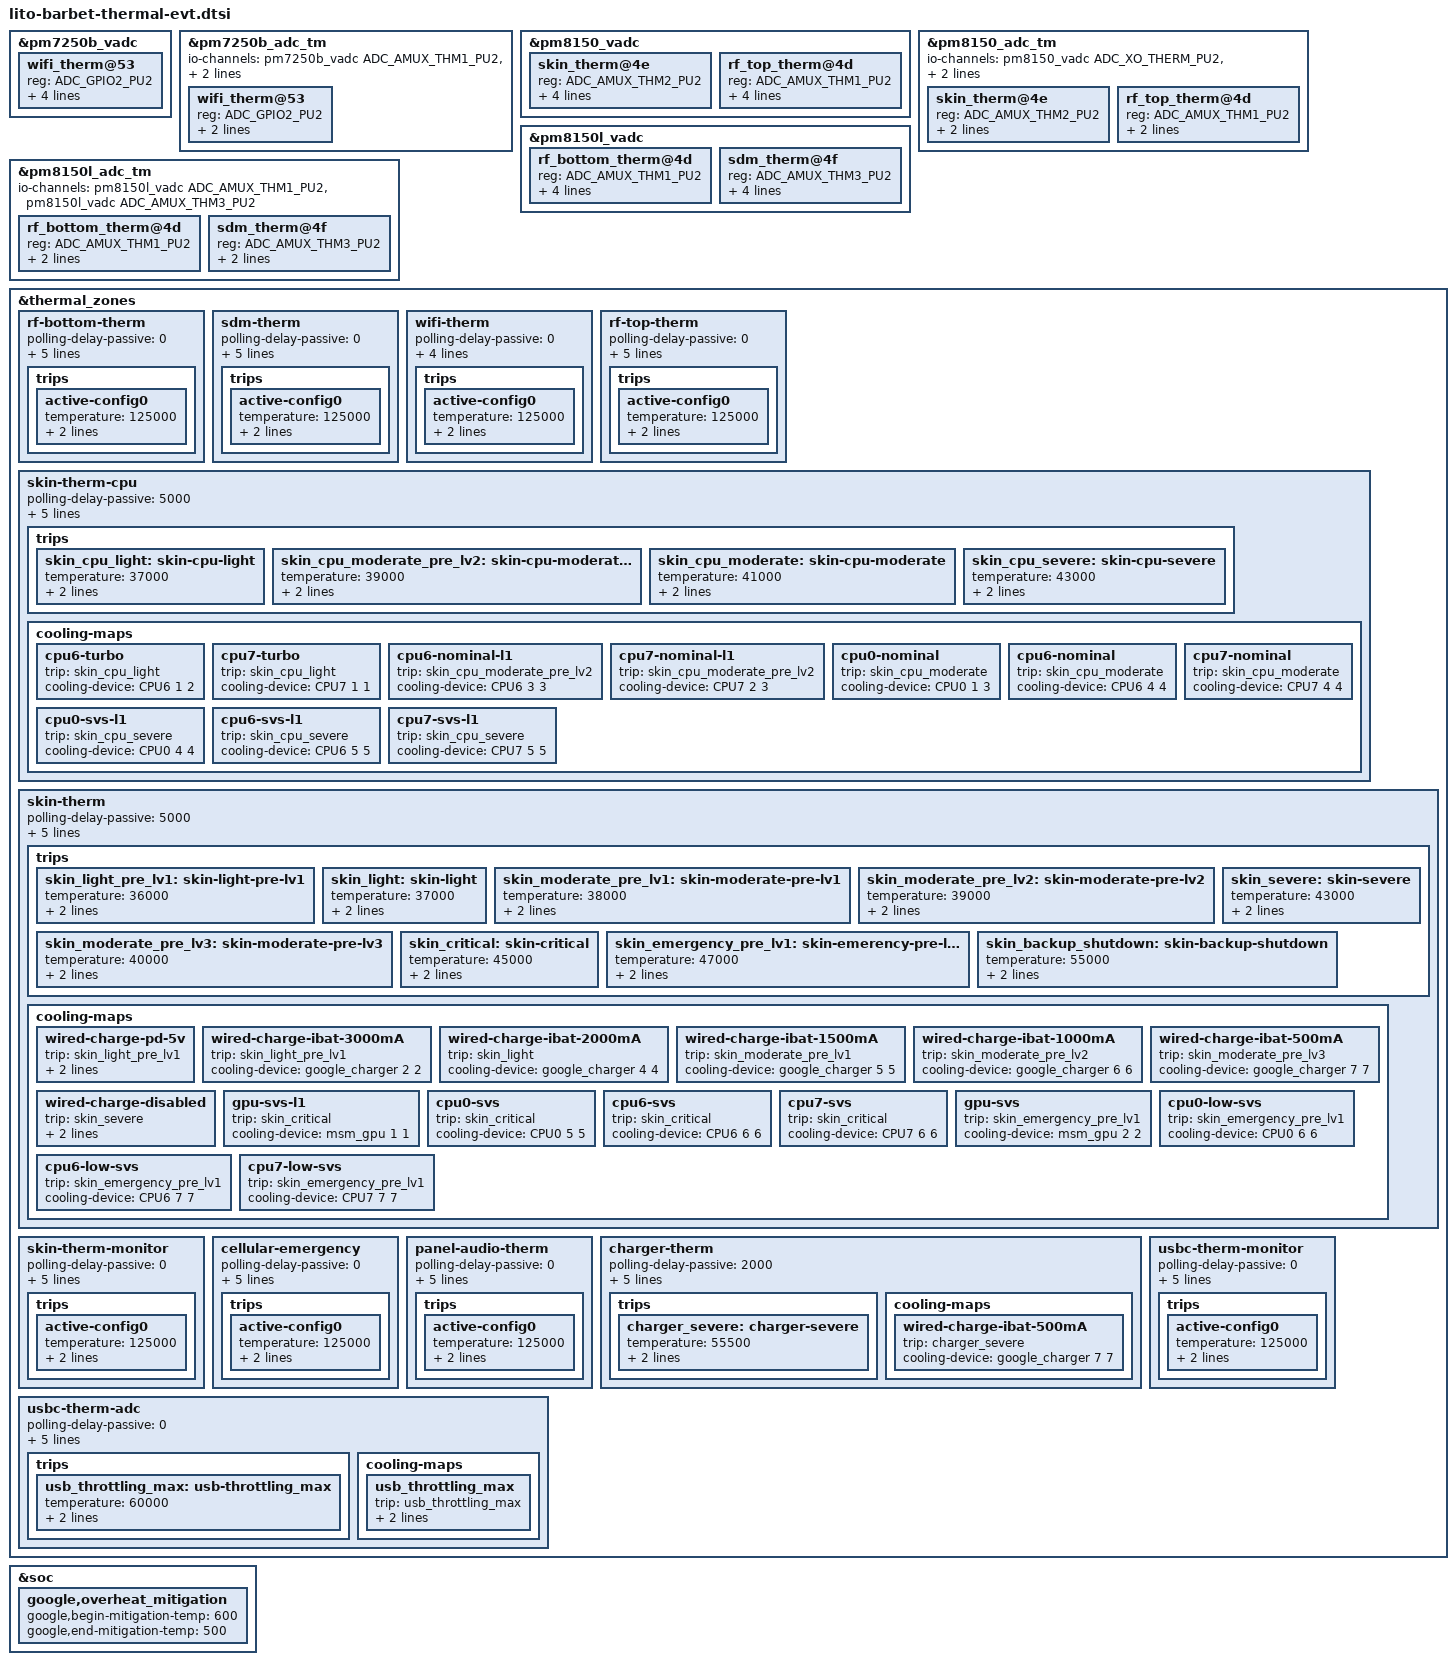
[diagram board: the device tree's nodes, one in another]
// SPDX-License-Identifier: GPL-2.0
/* Copyright (c) 2019, The Linux Foundation. All rights reserved.
 *
 * This program is free software; you can redistribute it and/or modify
 * it under the terms of the GNU General Public License version 2 and
 * only version 2 as published by the Free Software Foundation.
 *
 * This program is distributed in the hope that it will be useful,
 * but WITHOUT ANY WARRANTY; without even the implied warranty of
 * MERCHANTABILITY or FITNESS FOR A PARTICULAR PURPOSE.  See the
 * GNU General Public License for more details.
 */

&pm7250b_vadc {
	wifi_therm@53 {
		reg = <ADC_GPIO2_PU2>;
		label = "wifi_therm";
		qcom,ratiometric;
		qcom,hw-settle-time = <200>;
		qcom,pre-scaling = <1 1>;
	};
};

&pm7250b_adc_tm {
	io-channels = <&pm7250b_vadc ADC_AMUX_THM1_PU2>,
			<&pm7250b_vadc ADC_AMUX_THM3_PU2>,
			<&pm7250b_vadc ADC_GPIO2_PU2>;

	wifi_therm@53 {
		reg = <ADC_GPIO2_PU2>;
		qcom,ratiometric;
		qcom,hw-settle-time = <200>;
	};
};

&pm8150_vadc {
	skin_therm@4e {
		reg = <ADC_AMUX_THM2_PU2>;
		label = "skin_therm";
		qcom,ratiometric;
		qcom,hw-settle-time = <200>;
		qcom,pre-scaling = <1 1>;
	};

	rf_top_therm@4d {
		reg = <ADC_AMUX_THM1_PU2>;
		label = "rf_top_therm";
		qcom,ratiometric;
		qcom,hw-settle-time = <200>;
		qcom,pre-scaling = <1 1>;
	};
};

&pm8150_adc_tm {
	io-channels = <&pm8150_vadc ADC_XO_THERM_PU2>,
			<&pm8150_vadc ADC_AMUX_THM1_PU2>,
			<&pm8150_vadc ADC_AMUX_THM2_PU2>;

	skin_therm@4e {
		reg = <ADC_AMUX_THM2_PU2>;
		qcom,ratiometric;
		qcom,hw-settle-time = <200>;
	};

	rf_top_therm@4d {
		reg = <ADC_AMUX_THM1_PU2>;
		qcom,ratiometric;
		qcom,hw-settle-time = <200>;
	};
};

&pm8150l_vadc {

	rf_bottom_therm@4d {
		reg = <ADC_AMUX_THM1_PU2>;
		label = "rf_bottom_therm";
		qcom,ratiometric;
		qcom,hw-settle-time = <200>;
		qcom,pre-scaling = <1 1>;
	};

	sdm_therm@4f {
		reg = <ADC_AMUX_THM3_PU2>;
		label = "sdm_therm";
		qcom,ratiometric;
		qcom,hw-settle-time = <200>;
		qcom,pre-scaling = <1 1>;
	};
};

&pm8150l_adc_tm {
	io-channels = <&pm8150l_vadc ADC_AMUX_THM1_PU2>,
			<&pm8150l_vadc ADC_AMUX_THM3_PU2>;

	/* Channel nodes */
	rf_bottom_therm@4d {
		reg = <ADC_AMUX_THM1_PU2>;
		qcom,ratiometric;
		qcom,hw-settle-time = <200>;
	};

	sdm_therm@4f {
		reg = <ADC_AMUX_THM3_PU2>;
		qcom,ratiometric;
		qcom,hw-settle-time = <200>;
	};
};

&thermal_zones {
	rf-bottom-therm {
		polling-delay-passive = <0>;
		polling-delay = <0>;
		thermal-governor = "user_space";
		thermal-sensors = <&pm8150l_adc_tm ADC_AMUX_THM1_PU2>;
		wake-capable-sensor;
		trips {
			active-config0 {
				temperature = <125000>;
				hysteresis = <1000>;
				type = "passive";
			};
		};
	};

	sdm-therm {
		polling-delay-passive = <0>;
		polling-delay = <0>;
		thermal-governor = "user_space";
		thermal-sensors = <&pm8150l_adc_tm ADC_AMUX_THM3_PU2>;
		wake-capable-sensor;
		trips {
			active-config0 {
				temperature = <125000>;
				hysteresis = <1000>;
				type = "passive";
			};
		};
	};

	wifi-therm {
		polling-delay-passive = <0>;
		polling-delay = <0>;
		thermal-governor = "user_space";
		thermal-sensors = <&pm7250b_adc_tm ADC_GPIO2_PU2>;
		wake-capable-sensor;
		trips {
			active-config0 {
				temperature = <125000>;
				hysteresis = <1000>;
				type = "passive";
			};
		};
	};

	rf-top-therm {
		polling-delay-passive = <0>;
		polling-delay = <0>;
		thermal-governor = "user_space";
		thermal-sensors = <&pm8150_adc_tm ADC_AMUX_THM1_PU2>;
		wake-capable-sensor;
		trips {
			active-config0 {
				temperature = <125000>;
				hysteresis = <1000>;
				type = "passive";
			};
		};
	};

	skin-therm-cpu {
		polling-delay-passive = <5000>;
		polling-delay = <300000>;
		thermal-governor = "step_wise";
		thermal-sensors = <&pm8150_adc_tm ADC_AMUX_THM2_PU2>;
		wake-capable-sensor;
		trips {
			skin_cpu_light: skin-cpu-light {
				temperature = <37000>;
				hysteresis = <1000>;
				type = "passive";
			};
			skin_cpu_moderate_pre_lv2: skin-cpu-moderate-pre-lv2 {
				temperature = <39000>;
				hysteresis = <1000>;
				type = "passive";
			};
			skin_cpu_moderate: skin-cpu-moderate {
				temperature = <41000>;
				hysteresis = <1000>;
				type = "passive";
			};
			skin_cpu_severe: skin-cpu-severe {
				temperature = <43000>;
				hysteresis = <1000>;
				type = "passive";
			};
		};
		cooling-maps {
			/* light throttling */
			cpu6-turbo {
				trip = <&skin_cpu_light>;
				cooling-device =
					<&CPU6 1 2>;
			};
			cpu7-turbo {
				trip = <&skin_cpu_light>;
				cooling-device =
					<&CPU7 1 1>;
			};
			/* moderate pre level 2 throttling */
			cpu6-nominal-l1 {
				trip = <&skin_cpu_moderate_pre_lv2>;
				cooling-device =
					<&CPU6 3 3>;
			};
			cpu7-nominal-l1 {
				trip = <&skin_cpu_moderate_pre_lv2>;
				cooling-device =
					<&CPU7 2 3>;
			};
			/* moderate throttling */
			cpu0-nominal {
				trip = <&skin_cpu_moderate>;
				cooling-device =
					<&CPU0 1 3>;
			};
			cpu6-nominal {
				trip = <&skin_cpu_moderate>;
				cooling-device =
					<&CPU6 4 4>;
			};
			cpu7-nominal {
				trip = <&skin_cpu_moderate>;
				cooling-device =
					<&CPU7 4 4>;
			};
			/* severe throttling */
			cpu0-svs-l1 {
				trip = <&skin_cpu_severe>;
				cooling-device =
					<&CPU0 4 4>;
			};
			cpu6-svs-l1 {
				trip = <&skin_cpu_severe>;
				cooling-device =
					<&CPU6 5 5>;
			};
			cpu7-svs-l1 {
				trip = <&skin_cpu_severe>;
				cooling-device =
					<&CPU7 5 5>;
			};
		};
	};

	skin-therm {
		polling-delay-passive = <5000>;
		polling-delay = <300000>;
		thermal-governor = "step_wise";
		thermal-sensors = <&pm8150_adc_tm ADC_AMUX_THM2_PU2>;
		wake-capable-sensor;
		trips {
			skin_light_pre_lv1: skin-light-pre-lv1 {
				temperature = <36000>;
				hysteresis = <1000>;
				type = "passive";
			};
			skin_light: skin-light {
				temperature = <37000>;
				hysteresis = <1000>;
				type = "passive";
			};
			skin_moderate_pre_lv1: skin-moderate-pre-lv1 {
				temperature = <38000>;
				hysteresis = <1000>;
				type = "passive";
			};
			skin_moderate_pre_lv2: skin-moderate-pre-lv2 {
				temperature = <39000>;
				hysteresis = <1000>;
				type = "passive";
			};
			skin_moderate_pre_lv3: skin-moderate-pre-lv3 {
				temperature = <40000>;
				hysteresis = <1000>;
				type = "passive";
			};
			skin_severe: skin-severe {
				temperature = <43000>;
				hysteresis = <1000>;
				type = "passive";
			};
			skin_critical: skin-critical {
				temperature = <45000>;
				hysteresis = <1000>;
				type = "passive";
			};
			skin_emergency_pre_lv1: skin-emerency-pre-lv1 {
				temperature = <47000>;
				hysteresis = <1000>;
				type = "passive";
			};
			skin_backup_shutdown: skin-backup-shutdown {
				temperature = <55000>;
				hysteresis = <1000>;
				type = "critical";
			};
		};
		cooling-maps {
			/* light pre level 1 throttling */
			wired-charge-pd-5v {
				trip = <&skin_light_pre_lv1>;
				cooling-device = <&google_charger_pd_5v
					THERMAL_MAX_LIMIT THERMAL_MAX_LIMIT>;
			};
			wired-charge-ibat-3000mA {
				trip = <&skin_light_pre_lv1>;
				cooling-device =
					<&google_charger 2 2>;
			};
			/* light throttling */
			wired-charge-ibat-2000mA {
				trip = <&skin_light>;
				cooling-device =
					<&google_charger 4 4>;
			};
			/* moderate pre level 1 throttling */
			wired-charge-ibat-1500mA {
				trip = <&skin_moderate_pre_lv1>;
				cooling-device =
					<&google_charger 5 5>;
			};
			/* moderate pre level 2 throttling */
			wired-charge-ibat-1000mA {
				trip = <&skin_moderate_pre_lv2>;
				cooling-device =
					<&google_charger 6 6>;
			};
			/* moderate pre level 3 throttling */
			wired-charge-ibat-500mA {
				trip = <&skin_moderate_pre_lv3>;
				cooling-device =
					<&google_charger 7 7>;
			};
			/* severe throttling */
			wired-charge-disabled {
				trip = <&skin_severe>;
				cooling-device = <&google_charger
					THERMAL_MAX_LIMIT THERMAL_MAX_LIMIT>;
			};
			/* critical throttling */
			gpu-svs-l1 {
				trip = <&skin_critical>;
				cooling-device = <&msm_gpu 1 1>;
			};
			cpu0-svs {
				trip = <&skin_critical>;
				cooling-device =
					<&CPU0 5 5>;
			};
			cpu6-svs {
				trip = <&skin_critical>;
				cooling-device =
					<&CPU6 6 6>;
			};
			cpu7-svs {
				trip = <&skin_critical>;
				cooling-device =
					<&CPU7 6 6>;
			};
			/* emergency pre level 1 throttling */
			gpu-svs {
				trip = <&skin_emergency_pre_lv1>;
				cooling-device =
					<&msm_gpu 2 2>;
			};
			cpu0-low-svs {
				trip = <&skin_emergency_pre_lv1>;
				cooling-device =
					<&CPU0 6 6>;
			};
			cpu6-low-svs {
				trip = <&skin_emergency_pre_lv1>;
				cooling-device =
					<&CPU6 7 7>;
			};
			cpu7-low-svs {
				trip = <&skin_emergency_pre_lv1>;
				cooling-device =
					<&CPU7 7 7>;
			};
		};
	};

	skin-therm-monitor {
		polling-delay-passive = <0>;
		polling-delay = <0>;
		thermal-governor = "user_space";
		thermal-sensors = <&pm8150_adc_tm ADC_AMUX_THM2_PU2>;
		wake-capable-sensor;
		trips {
			active-config0 {
				temperature = <125000>;
				hysteresis = <1000>;
				type = "passive";
			};
		};
	};

	cellular-emergency {
		polling-delay-passive = <0>;
		polling-delay = <0>;
		thermal-governor = "user_space";
		thermal-sensors = <&pm8150_adc_tm ADC_AMUX_THM2_PU2>;
		wake-capable-sensor;
		trips {
			active-config0 {
				temperature = <125000>;
				hysteresis = <1000>;
				type = "passive";
			};
		};
	};

	panel-audio-therm {
		polling-delay-passive = <0>;
		polling-delay = <0>;
		thermal-governor = "user_space";
		thermal-sensors = <&pm8150_adc_tm ADC_AMUX_THM2_PU2>;
		wake-capable-sensor;
		trips {
			active-config0 {
				temperature = <125000>;
				hysteresis = <1000>;
				type = "passive";
			};
		};
	};

	charger-therm {
		polling-delay-passive = <2000>;
		polling-delay = <0>;
		thermal-governor = "step_wise";
		thermal-sensors = <&pm7250b_adc_tm ADC_AMUX_THM1_PU2>;
		wake-capable-sensor;
		trips {
			charger_severe: charger-severe {
				temperature = <55500>;
				hysteresis = <10000>;
				type = "passive";
			};
		};
		cooling-maps {
			wired-charge-ibat-500mA {
				trip = <&charger_severe>;
				cooling-device =
				<&google_charger 7 7>;
			};
		};
	};

	usbc-therm-adc {
		polling-delay-passive = <0>;
		polling-delay = <0>;
		thermal-governor = "step_wise";
		thermal-sensors = <&pm7250b_adc_tm ADC_AMUX_THM3_PU2>;
		wake-capable-sensor;
		trips {
			usb_throttling_max: usb-throttling_max {
				temperature = <60000>;
				hysteresis = <10000>;
				type = "passive";
			};
		};
		cooling-maps {
			usb_throttling_max {
				trip = <&usb_throttling_max>;
				cooling-device =
					<&google_overheat_mitigation
					THERMAL_MAX_LIMIT THERMAL_MAX_LIMIT>;
			};
		};
	};

	usbc-therm-monitor {
		polling-delay-passive = <0>;
		polling-delay = <0>;
		thermal-governor = "user_space";
		thermal-sensors = <&pm7250b_adc_tm ADC_AMUX_THM3_PU2>;
		wake-capable-sensor;
		trips {
			active-config0 {
				temperature = <125000>;
				hysteresis = <1000>;
				type = "passive";
			};
		};
	};
};

&soc {
	google,overheat_mitigation {
		google,begin-mitigation-temp = <600>;
		google,end-mitigation-temp = <500>;
	};
};
